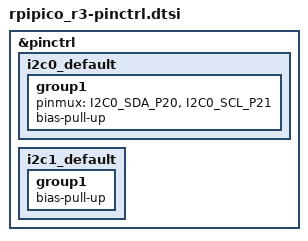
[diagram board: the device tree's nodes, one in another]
/*
 * Copyright (c) 2024 TiaC Systems
 * SPDX-License-Identifier: Apache-2.0
 */

#include <zephyr/dt-bindings/pinctrl/rpi-pico-rp2040-pinctrl.h>

&pinctrl {
	i2c0_default: i2c0_default {
		group1 {
			pinmux = <I2C0_SDA_P20>, <I2C0_SCL_P21>;
			bias-pull-up;
		};
	};
	i2c1_default: i2c1_default {
		group1 {
			bias-pull-up;
		};
	};
};
